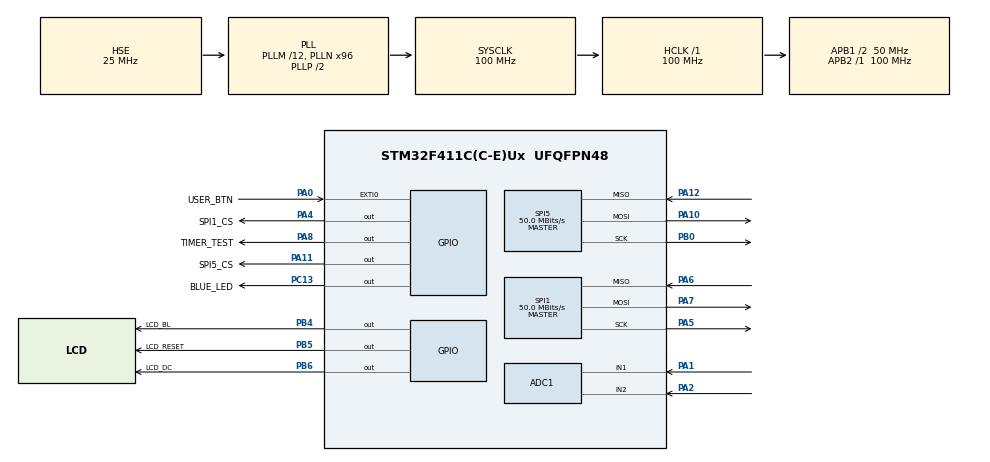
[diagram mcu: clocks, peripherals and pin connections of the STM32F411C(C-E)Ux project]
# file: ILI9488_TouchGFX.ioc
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ADC1.Channel-4\#ChannelRegularConversion=ADC_CHANNEL_1
ADC1.Channel-5\#ChannelRegularConversion=ADC_CHANNEL_1
ADC1.ClockPrescaler=ADC_CLOCK_SYNC_PCLK_DIV8
ADC1.ContinuousConvMode=ENABLE
ADC1.NbrOfConversion=2
ADC1.NbrOfConversionFlag=1
ADC1.Rank-4\#ChannelRegularConversion=1
ADC1.Rank-5\#ChannelRegularConversion=2
ADC1.SamplingTime-4\#ChannelRegularConversion=ADC_SAMPLETIME_480CYCLES
ADC1.SamplingTime-5\#ChannelRegularConversion=ADC_SAMPLETIME_480CYCLES
ADC1.ScanConvMode=ENABLE
ADC1.master=1
Dma.ADC1.0.Direction=DMA_PERIPH_TO_MEMORY
Dma.ADC1.0.FIFOMode=DMA_FIFOMODE_DISABLE
Dma.ADC1.0.Instance=DMA2_Stream0
Dma.ADC1.0.MemDataAlignment=DMA_MDATAALIGN_HALFWORD
Dma.ADC1.0.MemInc=DMA_MINC_ENABLE
Dma.ADC1.0.Mode=DMA_CIRCULAR
Dma.ADC1.0.PeriphDataAlignment=DMA_PDATAALIGN_HALFWORD
Dma.ADC1.0.PeriphInc=DMA_PINC_DISABLE
Dma.ADC1.0.Priority=DMA_PRIORITY_LOW
Dma.Request0=ADC1
Dma.Request1=SPI5_TX
Dma.SPI5_TX.1.Direction=DMA_MEMORY_TO_PERIPH
Dma.SPI5_TX.1.FIFOMode=DMA_FIFOMODE_DISABLE
Dma.SPI5_TX.1.Instance=DMA2_Stream4
Dma.SPI5_TX.1.MemDataAlignment=DMA_MDATAALIGN_BYTE
Dma.SPI5_TX.1.MemInc=DMA_MINC_ENABLE
Dma.SPI5_TX.1.Mode=DMA_NORMAL
Dma.SPI5_TX.1.PeriphDataAlignment=DMA_PDATAALIGN_BYTE
Dma.SPI5_TX.1.PeriphInc=DMA_PINC_DISABLE
Dma.SPI5_TX.1.Priority=DMA_PRIORITY_LOW
Mcu.Family=STM32F4
Mcu.Name=STM32F411C(C-E)Ux
Mcu.Package=UFQFPN48
NVIC.ADC_IRQn=true\:0\:0\:false\:false\:true\:true\:true\:true
NVIC.DMA2_Stream0_IRQn=true\:0\:0\:false\:false\:true\:false\:true\:true
NVIC.DMA2_Stream4_IRQn=true\:0\:0\:false\:false\:true\:false\:true\:true
NVIC.EXTI0_IRQn=true\:0\:0\:false\:false\:true\:true\:true\:true
NVIC.PriorityGroup=NVIC_PRIORITYGROUP_4
NVIC.SPI1_IRQn=true\:0\:0\:false\:false\:true\:true\:true\:true
NVIC.SPI5_IRQn=true\:0\:0\:false\:false\:true\:true\:true\:true
NVIC.TIM1_BRK_TIM9_IRQn=true\:0\:0\:false\:false\:true\:true\:true\:true
PA0-WKUP.GPIO_Label=USER_BTN
PA0-WKUP.GPIO_ModeDefaultEXTI=GPIO_MODE_IT_FALLING
PA0-WKUP.GPIO_PuPd=GPIO_PULLUP
PA0-WKUP.Signal=GPXTI0
PA1.Signal=ADCx_IN1
PA10.Mode=Full_Duplex_Master
PA10.Signal=SPI5_MOSI
PA11.GPIO_Label=SPI5_CS
PA11.GPIO_PuPd=GPIO_PULLUP
PA11.GPIO_Speed=GPIO_SPEED_FREQ_VERY_HIGH
PA11.PinState=GPIO_PIN_SET
PA11.Signal=GPIO_Output
PA12.Mode=Full_Duplex_Master
PA12.Signal=SPI5_MISO
PA13.Mode=Serial_Wire
PA13.Signal=SYS_JTMS-SWDIO
PA14.Mode=Serial_Wire
PA14.Signal=SYS_JTCK-SWCLK
PA2.Signal=ADCx_IN2
PA4.GPIO_Label=SPI1_CS
PA4.GPIO_PuPd=GPIO_PULLUP
PA4.GPIO_Speed=GPIO_SPEED_FREQ_HIGH
PA4.PinState=GPIO_PIN_SET
PA4.Signal=GPIO_Output
PA5.Mode=Full_Duplex_Master
PA5.Signal=SPI1_SCK
PA6.Mode=Full_Duplex_Master
PA6.Signal=SPI1_MISO
PA7.Mode=Full_Duplex_Master
PA7.Signal=SPI1_MOSI
PA8.GPIO_Label=TIMER_TEST
PA8.GPIO_Speed=GPIO_SPEED_FREQ_HIGH
PA8.Signal=GPIO_Output
PB0.Mode=Full_Duplex_Master
PB0.Signal=SPI5_SCK
PB4.GPIO_Label=LCD_BL
PB4.Signal=GPIO_Output
PB5.GPIO_Label=LCD_RESET
PB5.Signal=GPIO_Output
PB6.GPIO_Label=LCD_DC
PB6.Signal=GPIO_Output
PC13-ANTI_TAMP.GPIO_Label=BLUE_LED
PC13-ANTI_TAMP.Signal=GPIO_Output
PH0\ -\ OSC_IN.Mode=HSE-External-Oscillator
PH0\ -\ OSC_IN.Signal=RCC_OSC_IN
PH1\ -\ OSC_OUT.Mode=HSE-External-Oscillator
PH1\ -\ OSC_OUT.Signal=RCC_OSC_OUT
ProjectManager.HeapSize=0x2000
ProjectManager.StackSize=0x4000
ProjectManager.TargetToolchain=MDK-ARM V5.32
RCC.48MHZClocksFreq_Value=50000000
RCC.AHBFreq_Value=100000000
RCC.APB1CLKDivider=RCC_HCLK_DIV2
RCC.APB1Freq_Value=50000000
RCC.APB1TimFreq_Value=100000000
RCC.APB2Freq_Value=100000000
RCC.APB2TimFreq_Value=100000000
RCC.CortexFreq_Value=100000000
RCC.HCLKFreq_Value=100000000
RCC.HSE_VALUE=25000000
RCC.HSI_VALUE=16000000
RCC.LSE_VALUE=32768
RCC.PLLM=12
RCC.PLLN=96
RCC.PLLSourceVirtual=RCC_PLLSOURCE_HSE
RCC.SYSCLKFreq_VALUE=100000000
RCC.SYSCLKSource=RCC_SYSCLKSOURCE_PLLCLK
RCC.VCOOutputFreq_Value=200000000
SH.ADCx_IN1.0=ADC1_IN1,IN1
SH.ADCx_IN2.0=ADC1_IN2,IN2
SPI1.CalculateBaudRate=50.0 MBits/s
SPI1.Direction=SPI_DIRECTION_2LINES
SPI1.Mode=SPI_MODE_MASTER
SPI1.VirtualType=VM_MASTER
SPI5.CalculateBaudRate=50.0 MBits/s
SPI5.Direction=SPI_DIRECTION_2LINES
SPI5.Mode=SPI_MODE_MASTER
SPI5.VirtualType=VM_MASTER
STMicroelectronics.X-CUBE-TOUCHGFX.4.22.0.ApplicationCcGraphicsJjApplication=TouchGFXOoGenerator
STMicroelectronics.X-CUBE-TOUCHGFX.4.22.0.tgfx_buffering_strategy=Partial
STMicroelectronics.X-CUBE-TOUCHGFX.4.22.0.tgfx_custom_height=320
STMicroelectronics.X-CUBE-TOUCHGFX.4.22.0.tgfx_custom_width=480
STMicroelectronics.X-CUBE-TOUCHGFX.4.22.0.tgfx_partialfb_transmit_strategy=Enabled
STMicroelectronics.X-CUBE-TOUCHGFX.4.22.0_IsPackSelfContextualization=true
TIM9.AutoReloadPreload=TIM_AUTORELOAD_PRELOAD_ENABLE
TIM9.Period=16666
TIM9.Prescaler=100-1
VP_CRC_VS_CRC.Mode=CRC_Activate
VP_STMicroelectronics.X-CUBE-TOUCHGFX_VS_GraphicsJjApplication_4.22.0.Mode=GraphicsJjApplication
VP_TIM9_VS_ClockSourceINT.Mode=Internal
board=custom

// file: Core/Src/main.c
/* USER CODE BEGIN Header */
/**
  ******************************************************************************
  * @file           : main.c
  * @brief          : Main program body
  ******************************************************************************
  * @attention
  *
  * Copyright (c) 2023 STMicroelectronics.
  * All rights reserved.
  *
  * This software is licensed under terms that can be found in the LICENSE file
  * in the root directory of this software component.
  * If no LICENSE file comes with this software, it is provided AS-IS.
  *
  ******************************************************************************
  */
/* USER CODE END Header */
#include "main.h"
#include "adc.h"
#include "crc.h"
#include "dma.h"
#include "spi.h"
#include "tim.h"
#include "gpio.h"
#include "app_touchgfx.h"

void SystemClock_Config(void);

int main(void)
{

  /* MCU Configuration--------------------------------------------------------*/

  /* Reset of all peripherals, Initializes the Flash interface and the Systick. */
  HAL_Init();

  /* Configure the system clock */
  SystemClock_Config();

  /* Initialize all configured peripherals */
  MX_GPIO_Init();
  MX_DMA_Init();
  MX_ADC1_Init();
  MX_SPI5_Init();
  MX_CRC_Init();
  MX_TIM9_Init();
  MX_SPI1_Init();
  MX_TouchGFX_Init();

  /* USER CODE BEGIN 2 */
	Displ_Init(Displ_Orientat_90);		// initialize display controller - set orientation parameter as per TouchGFX setup
	Displ_BackLight('1');  			// initialize backlight
	HAL_TIM_Base_Start_IT(&TGFX_T);		// starting timer driving touchgfxSignalVSync()
  /* USER CODE END 2 */

  /* Infinite loop */
  while (1)
  {

  MX_TouchGFX_Process();
  }
}

void SystemClock_Config(void)
{
  RCC_OscInitTypeDef RCC_OscInitStruct = {0};
  RCC_ClkInitTypeDef RCC_ClkInitStruct = {0};

  /** Configure the main internal regulator output voltage
  */
  __HAL_RCC_PWR_CLK_ENABLE();
  __HAL_PWR_VOLTAGESCALING_CONFIG(PWR_REGULATOR_VOLTAGE_SCALE1);

  /** Initializes the RCC Oscillators according to the specified parameters
  * in the RCC_OscInitTypeDef structure.
  */
  RCC_OscInitStruct.OscillatorType = RCC_OSCILLATORTYPE_HSE;
  RCC_OscInitStruct.HSEState = RCC_HSE_ON;
  RCC_OscInitStruct.PLL.PLLState = RCC_PLL_ON;
  RCC_OscInitStruct.PLL.PLLSource = RCC_PLLSOURCE_HSE;
  RCC_OscInitStruct.PLL.PLLM = 12;
  RCC_OscInitStruct.PLL.PLLN = 96;
  RCC_OscInitStruct.PLL.PLLP = RCC_PLLP_DIV2;
  RCC_OscInitStruct.PLL.PLLQ = 4;
  if (HAL_RCC_OscConfig(&RCC_OscInitStruct) != HAL_OK)
  {
    Error_Handler();
  }

  /** Initializes the CPU, AHB and APB buses clocks
  */
  RCC_ClkInitStruct.ClockType = RCC_CLOCKTYPE_HCLK|RCC_CLOCKTYPE_SYSCLK
                              |RCC_CLOCKTYPE_PCLK1|RCC_CLOCKTYPE_PCLK2;
  RCC_ClkInitStruct.SYSCLKSource = RCC_SYSCLKSOURCE_PLLCLK;
  RCC_ClkInitStruct.AHBCLKDivider = RCC_SYSCLK_DIV1;
  RCC_ClkInitStruct.APB1CLKDivider = RCC_HCLK_DIV2;
  RCC_ClkInitStruct.APB2CLKDivider = RCC_HCLK_DIV1;

  if (HAL_RCC_ClockConfig(&RCC_ClkInitStruct, FLASH_LATENCY_3) != HAL_OK)
  {
    Error_Handler();
  }
}

void Error_Handler(void)
{
  __disable_irq();
  while (1)
  {
  }
}
